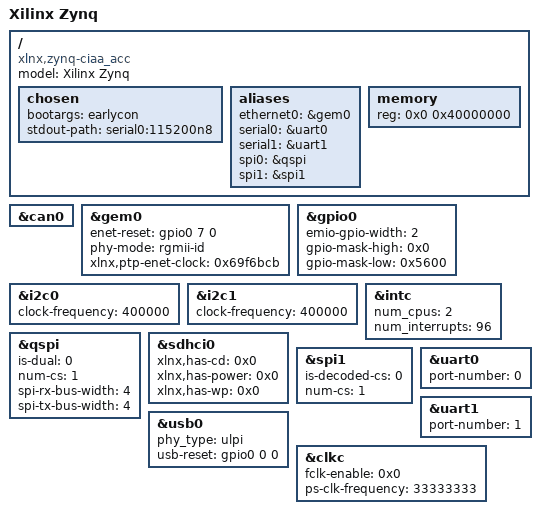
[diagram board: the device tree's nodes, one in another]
/*
 * Device Tree Generator version: 1.1
 *
 *
 * (C) Copyright 2007-2017 Xilinx, Inc.
 * (C) Copyright      2017 Martin Ribelotta@emtech
 * Martin Ribelotta <mribelotta@emtech.com.ar>
 *
 * CAUTION: This file is automatically generated by Xilinx.
 * Version: Today is: Sat Nov 11 16:59:04 2017
 */

/dts-v1/;
/include/ "zynq-7000.dtsi"

/ {
	compatible = "xlnx,zynq-ciaa_acc", "xlnx,zynq-7000";
	model = "Xilinx Zynq";

	chosen {
		bootargs = "earlycon";
		stdout-path = "serial0:115200n8";
	};
	aliases {
		ethernet0 = &gem0;
		serial0 = &uart0;
		serial1 = &uart1;
		spi0 = &qspi;
		spi1 = &spi1;
	};
	memory {
		device_type = "memory";
		reg = <0x0 0x40000000>;
	};
};


&can0 {
	status = "okay";
};

&gem0 {
	enet-reset = <&gpio0 7 0>;
	phy-mode = "rgmii-id";
	status = "okay";
	xlnx,ptp-enet-clock = <0x69f6bcb>;
};

&gpio0 {
	emio-gpio-width = <2>;
	gpio-mask-high = <0x0>;
	gpio-mask-low = <0x5600>;
};

&i2c0 {
	clock-frequency = <400000>;
	status = "okay";
};

&i2c1 {
	clock-frequency = <400000>;
	status = "okay";
};

&intc {
	num_cpus = <2>;
	num_interrupts = <96>;
};

&qspi {
	is-dual = <0>;
	num-cs = <1>;
	spi-rx-bus-width = <4>;
	spi-tx-bus-width = <4>;
	status = "okay";
};

&sdhci0 {
	status = "okay";
	xlnx,has-cd = <0x0>;
	xlnx,has-power = <0x0>;
	xlnx,has-wp = <0x0>;
};

&spi1 {
	is-decoded-cs = <0>;
	num-cs = <1>;
	status = "okay";
};

&uart0 {
	device_type = "serial";
	port-number = <0>;
	status = "okay";
};

&uart1 {
	device_type = "serial";
	port-number = <1>;
	status = "okay";
};

&usb0 {
	phy_type = "ulpi";
	status = "okay";
	usb-reset = <&gpio0 0 0>;
};

&clkc {
	fclk-enable = <0x0>;
	ps-clk-frequency = <33333333>;
};
